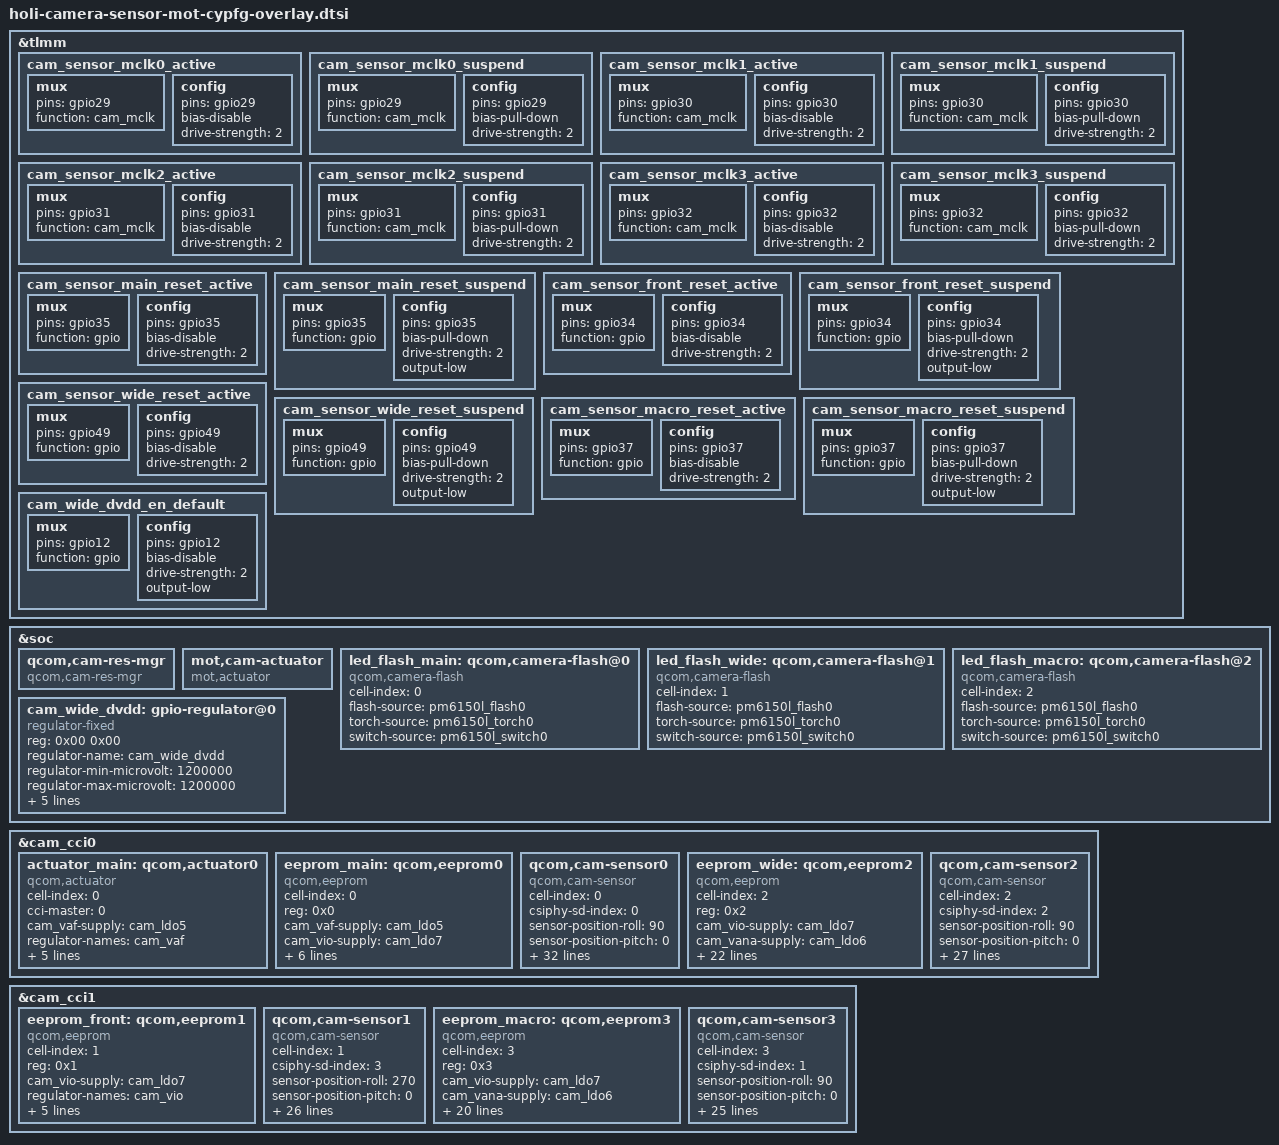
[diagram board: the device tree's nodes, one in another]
#include <dt-bindings/clock/qcom,gcc-holi.h>

&tlmm {
	cam_sensor_mclk0_active: cam_sensor_mclk0_active {
		mux {
			pins = "gpio29";
			function = "cam_mclk";
		};

		config {
			pins = "gpio29";
			bias-disable; /* No PULL */
			drive-strength = <2>; /* 2 MA */
		};
	};

	cam_sensor_mclk0_suspend: cam_sensor_mclk0_suspend {
		mux {
			pins = "gpio29";
			function = "cam_mclk";
		};

		config {
			pins = "gpio29";
			bias-pull-down; /* PULL DOWN */
			drive-strength = <2>; /* 2 MA */
		};
	};

	cam_sensor_mclk1_active: cam_sensor_mclk1_active {
		mux {
			pins = "gpio30";
			function = "cam_mclk";
		};

		config {
			pins = "gpio30";
			bias-disable; /* No PULL */
			drive-strength = <2>;
		};
	};

	cam_sensor_mclk1_suspend: cam_sensor_mclk1_suspend {
		mux {
			pins = "gpio30";
			function = "cam_mclk";
		};

		config {
			pins = "gpio30";
			bias-pull-down; /* PULL DOWN */
			drive-strength = <2>;
		};
	};

	cam_sensor_mclk2_active: cam_sensor_mclk2_active {
		mux {
			pins = "gpio31";
			function = "cam_mclk";
		};

		config {
			pins = "gpio31";
			bias-disable; /* No PULL */
			drive-strength = <2>;
		};
	};

	cam_sensor_mclk2_suspend: cam_sensor_mclk2_suspend {
		mux {
			pins = "gpio31";
			function = "cam_mclk";
		};

		config {
			pins = "gpio31";
			bias-pull-down; /* PULL DOWN */
			drive-strength = <2>;
		};
	};

	cam_sensor_mclk3_active: cam_sensor_mclk3_active {
		mux {
			pins = "gpio32";
			function = "cam_mclk";
		};

		config {
			pins = "gpio32";
			bias-disable; /* No PULL */
			drive-strength = <2>; /* 2 MA */
		};
	};

	cam_sensor_mclk3_suspend: cam_sensor_mclk3_suspend {
		mux {
			pins = "gpio32";
			function = "cam_mclk";
		};

		config {
			pins = "gpio32";
			bias-pull-down; /* PULL DOWN */
			drive-strength = <2>; /* 2 MA */
		};
	};

	cam_sensor_main_reset_active: cam_sensor_main_reset_active {
		mux {
			pins = "gpio35";
			function = "gpio";
		};

		config {
			pins = "gpio35";
			bias-disable; /* No PULL */
			drive-strength = <2>; /* 2 MA */
		};
	};

	cam_sensor_main_reset_suspend: cam_sensor_main_reset_suspend {
		mux {
			pins = "gpio35";
			function = "gpio";
		};

		config {
			pins = "gpio35";
			bias-pull-down; /* PULL DOWN */
			drive-strength = <2>; /* 2 MA */
			output-low;
		};
	};

	cam_sensor_front_reset_active: cam_sensor_front_reset_active {
		mux {
			pins = "gpio34";
			function = "gpio";
		};

		config {
			pins = "gpio34";
			bias-disable; /* No PULL */
			drive-strength = <2>; /* 2 MA */
		};
	};

	cam_sensor_front_reset_suspend: cam_sensor_front_reset_suspend {
		mux {
			pins = "gpio34";
			function = "gpio";
		};

		config {
			pins = "gpio34";
			bias-pull-down; /* PULL DOWN */
			drive-strength = <2>; /* 2 MA */
			output-low;
		};
	};

	cam_sensor_wide_reset_active: cam_sensor_wide_reset_active {
		mux {
			pins = "gpio49";
			function = "gpio";
		};

		config {
			pins = "gpio49";
			bias-disable; /* No PULL */
			drive-strength = <2>; /* 2 MA */
		};
	};

	cam_sensor_wide_reset_suspend: cam_sensor_wide_reset_suspend {
		mux {
			pins = "gpio49";
			function = "gpio";
		};

		config {
			pins = "gpio49";
			bias-pull-down; /* PULL DOWN */
			drive-strength = <2>; /* 2 MA */
			output-low;
		};
	};

	cam_sensor_macro_reset_active: cam_sensor_macro_reset_active {
		mux {
			pins = "gpio37";
			function = "gpio";
		};

		config {
			pins = "gpio37";
			bias-disable; /* No PULL */
			drive-strength = <2>; /* 2 MA */
		};
	};

	cam_sensor_macro_reset_suspend: cam_sensor_macro_reset_suspend {
		mux {
			pins = "gpio37";
			function = "gpio";
		};

		config {
			pins = "gpio37";
			bias-pull-down; /* PULL DOWN */
			drive-strength = <2>; /* 2 MA */
			output-low;
		};
	};

	cam_wide_dvdd_en_default: cam_wide_dvdd_en_default {
		mux {
			pins = "gpio12";
			function = "gpio";
		};

		config {
			pins = "gpio12";
			bias-disable; /* NO PULL */
			drive-strength = <2>; /* 2 MA */
			output-low;
		};
	};
};

&soc {
	qcom,cam-res-mgr {
		compatible = "qcom,cam-res-mgr";
		status = "ok";
	};

	mot,cam-actuator {
		compatible = "mot,actuator";
		status = "ok";
	};

	led_flash_main: qcom,camera-flash@0 {
		cell-index = <0>;
		compatible = "qcom,camera-flash";
		flash-source = <&pm6150l_flash0>;
		torch-source = <&pm6150l_torch0>;
		switch-source = <&pm6150l_switch0>;
		status = "ok";
	};

	led_flash_wide: qcom,camera-flash@1 {
		cell-index = <1>;
		compatible = "qcom,camera-flash";
		flash-source = <&pm6150l_flash0>;
		torch-source = <&pm6150l_torch0>;
		switch-source = <&pm6150l_switch0>;
		status = "ok";
	};

	led_flash_macro: qcom,camera-flash@2 {
		cell-index = <2>;
		compatible = "qcom,camera-flash";
		flash-source = <&pm6150l_flash0>;
		torch-source = <&pm6150l_torch0>;
		switch-source = <&pm6150l_switch0>;
		status = "ok";
	};

	cam_wide_dvdd: gpio-regulator@0{
		compatible = "regulator-fixed";
		reg = <0x00 0x00>;
		regulator-name = "cam_wide_dvdd";
		regulator-min-microvolt = <1200000>;
		regulator-max-microvolt = <1200000>;
		regulator-enable-ramp-delay = <233>;
		enable-active-high;
		gpio = <&tlmm 12 0>;
		pinctrl-names = "default";
		pinctrl-0 = <&cam_wide_dvdd_en_default>;
		vin-supply = <&S2A>;
	};
};

&cam_cci0 {
	actuator_main: qcom,actuator0 {
		cell-index = <0>;
		compatible = "qcom,actuator";
		cci-master = <0>;
		cam_vaf-supply = <&cam_ldo5>;
		regulator-names = "cam_vaf";
		rgltr-cntrl-support;
		rgltr-min-voltage = <2800000>;
		rgltr-max-voltage = <2800000>;
		rgltr-load-current = <100000>;
		status = "ok";
		multi-user-support;
	};

	eeprom_main: qcom,eeprom0 {
		cell-index = <0>;
		reg = <0x0>;
		compatible = "qcom,eeprom";
		cam_vaf-supply = <&cam_ldo5>;
		cam_vio-supply = <&cam_ldo7>;
		regulator-names = "cam_vaf", "cam_vio";
		rgltr-cntrl-support;
		rgltr-min-voltage = <2800000 1800000>;
		rgltr-max-voltage = <2800000 1800000>;
		rgltr-load-current = <100000 120000>;
		cci-master = <0>;
		status = "ok";
	};

	qcom,cam-sensor0 {
		cell-index = <0>;
		compatible = "qcom,cam-sensor";
		csiphy-sd-index = <0>;
		sensor-position-roll = <90>;
		sensor-position-pitch = <0>;
		sensor-position-yaw = <180>;
		actuator-src = <&actuator_main>;
		led-flash-src = <&led_flash_main>;
		eeprom-src = <&eeprom_main>;
		cam_vio-supply = <&cam_ldo7>;
		cam_vana-supply = <&cam_ldo4>;
		cam_vdig-supply = <&cam_ldo2>;
		cam_clk-supply = <&gcc_camss_top_gdsc>;
		cam_vaf-supply = <&cam_ldo5>;
		regulator-names = "cam_vio", "cam_vana", "cam_vdig",
			"cam_clk", "cam_vaf";
		rgltr-cntrl-support;
		rgltr-min-voltage = <1800000 2800000 1050000 0 2800000>;
		rgltr-max-voltage = <1800000 2800000 1050000 0 2800000>;
		rgltr-load-current = <120000 80000 1200000 0 100000>;
		gpio-no-mux = <0>;
		pinctrl-names = "cam_default", "cam_suspend";
		pinctrl-0 = <&cam_sensor_mclk0_active
				&cam_sensor_main_reset_active>;
		pinctrl-1 = <&cam_sensor_mclk0_suspend
				&cam_sensor_main_reset_suspend>;
		gpios = <&tlmm 29 0>,
			<&tlmm 35 0>;
		gpio-reset = <1>;
		gpio-req-tbl-num = <0 1>;
		gpio-req-tbl-flags = <1 0>;
		gpio-req-tbl-label = "CAMIF_MCLK0",
					"CAM_RESET0";
		cci-master = <0>;
		status = "ok";
		clocks = <&gcc GCC_CAMSS_MCLK0_CLK>;
		clock-names = "cam_clk";
		clock-cntl-level = "turbo";
		clock-rates = <24000000>;
	};

	eeprom_wide: qcom,eeprom2 {
		cell-index = <2>;
                reg = <0x2>;
		compatible = "qcom,eeprom";
		cam_vio-supply = <&cam_ldo7>;
		cam_vana-supply = <&cam_ldo6>;
		cam_vdig-supply = <&cam_wide_dvdd>;
		cam_clk-supply = <&gcc_camss_top_gdsc>;
		regulator-names = "cam_vio", "cam_vana", "cam_vdig",
			"cam_clk";
		rgltr-cntrl-support;
		rgltr-min-voltage = <1800000 2800000 1200000 0>;
		rgltr-max-voltage = <1800000 2800000 1200000 0>;
		rgltr-load-current = <120000 80000 1200000 0>;
		gpio-no-mux = <0>;
		pinctrl-names = "cam_default", "cam_suspend";
		pinctrl-0 = <&cam_sensor_mclk1_active
				&cam_sensor_wide_reset_active>;
		pinctrl-1 = <&cam_sensor_mclk1_suspend
				&cam_sensor_wide_reset_suspend>;
		gpios = <&tlmm 30 0>,
			<&tlmm 49 0>;
		gpio-reset = <1>;
		gpio-req-tbl-num = <0 1>;
		gpio-req-tbl-flags = <1 0>;
		gpio-req-tbl-label = "CAMIF_MCLK1",
					"CAM_RESET2";
		cci-master = <1>;
		status = "ok";
		clocks = <&gcc GCC_CAMSS_MCLK1_CLK>;
		clock-names = "cam_clk";
		clock-cntl-level = "turbo";
		clock-rates = <24000000>;
	};

	qcom,cam-sensor2 {
		cell-index = <2>;
		compatible = "qcom,cam-sensor";
		csiphy-sd-index = <2>;
		sensor-position-roll = <90>;
		sensor-position-pitch = <0>;
		sensor-position-yaw = <180>;
		led-flash-src = <&led_flash_wide>;
		eeprom-src = <&eeprom_wide>;
		cam_vio-supply = <&cam_ldo7>;
		cam_vana-supply = <&cam_ldo6>;
		cam_vdig-supply = <&cam_wide_dvdd>;
		cam_clk-supply = <&gcc_camss_top_gdsc>;
		regulator-names = "cam_vio", "cam_vana", "cam_vdig",
			"cam_clk";
		rgltr-cntrl-support;
		rgltr-min-voltage = <1800000 2800000 1200000 0>;
		rgltr-max-voltage = <1800000 2800000 1200000 0>;
		rgltr-load-current = <120000 80000 1200000 0>;
		gpio-no-mux = <0>;
		pinctrl-names = "cam_default", "cam_suspend";
		pinctrl-0 = <&cam_sensor_mclk1_active
				&cam_sensor_wide_reset_active>;
		pinctrl-1 = <&cam_sensor_mclk1_suspend
				&cam_sensor_wide_reset_suspend>;
		gpios = <&tlmm 30 0>,
			<&tlmm 49 0>;
		gpio-reset = <1>;
		gpio-req-tbl-num = <0 1>;
		gpio-req-tbl-flags = <1 0>;
		gpio-req-tbl-label = "CAMIF_MCLK1",
					"CAM_RESET2";
		cci-master = <1>;
		status = "ok";
		clocks = <&gcc GCC_CAMSS_MCLK1_CLK>;
		clock-names = "cam_clk";
		clock-cntl-level = "turbo";
		clock-rates = <24000000>;
	};
};

&cam_cci1 {
	eeprom_front: qcom,eeprom1 {
		cell-index = <1>;
		reg = <0x1>;
		compatible = "qcom,eeprom";
		cam_vio-supply = <&cam_ldo7>;
		regulator-names = "cam_vio";
		rgltr-cntrl-support;
		rgltr-min-voltage = <1800000>;
		rgltr-max-voltage = <1800000>;
		rgltr-load-current = <120000>;
		cci-master = <0>;
		status = "ok";
	};

	qcom,cam-sensor1 {
		cell-index = <1>;
		compatible = "qcom,cam-sensor";
		csiphy-sd-index = <3>;
		sensor-position-roll = <270>;
		sensor-position-pitch = <0>;
		sensor-position-yaw = <0>;
		eeprom-src = <&eeprom_front>;
		cam_vio-supply = <&cam_ldo7>;
		cam_vana-supply = <&cam_ldo3>;
		cam_vdig-supply = <&cam_ldo1>;
		cam_clk-supply = <&gcc_camss_top_gdsc>;
		regulator-names = "cam_vio", "cam_vana", "cam_vdig",
			"cam_clk";
		rgltr-cntrl-support;
		rgltr-min-voltage = <1800000 2800000 1050000 0>;
		rgltr-max-voltage = <1800000 2800000 1050000 0>;
		rgltr-load-current = <120000 80000 1200000 0>;
		gpio-no-mux = <0>;
		pinctrl-names = "cam_default", "cam_suspend";
		pinctrl-0 = <&cam_sensor_mclk3_active
				&cam_sensor_front_reset_active>;
		pinctrl-1 = <&cam_sensor_mclk3_suspend
				&cam_sensor_front_reset_suspend>;
		gpios = <&tlmm 32 0>,
			<&tlmm 34 0>;
		gpio-reset = <1>;
		gpio-req-tbl-num = <0 1>;
		gpio-req-tbl-flags = <1 0>;
		gpio-req-tbl-label = "CAMIF_MCLK3",
					"CAM_RESET1";
		cci-master = <0>;
		status = "ok";
		clocks = <&gcc GCC_CAMSS_MCLK3_CLK>;
		clock-names = "cam_clk";
		clock-cntl-level = "turbo";
		clock-rates = <24000000>;
	};

	eeprom_macro: qcom,eeprom3 {
		cell-index = <3>;
                reg = <0x3>;
		compatible = "qcom,eeprom";
		cam_vio-supply = <&cam_ldo7>;
		cam_vana-supply = <&cam_ldo6>;
		cam_clk-supply = <&gcc_camss_top_gdsc>;
		regulator-names = "cam_vio","cam_vana", "cam_clk";
		rgltr-cntrl-support;
		rgltr-min-voltage = <1800000 2800000 0>;
		rgltr-max-voltage = <1800000 2800000 0>;
		rgltr-load-current = <120000 120000  0>;
		gpio-no-mux = <0>;
		pinctrl-names = "cam_default", "cam_suspend";
		pinctrl-0 = <&cam_sensor_mclk2_active
				&cam_sensor_macro_reset_active>;
		pinctrl-1 = <&cam_sensor_mclk2_suspend
				&cam_sensor_macro_reset_suspend>;
		gpios = <&tlmm 31 0>,
			<&tlmm 37 0>;
		gpio-reset = <1>;
		gpio-req-tbl-num = <0 1>;
		gpio-req-tbl-flags = <1 0>;
		gpio-req-tbl-label = "CAMIF_MCLK2",
					"CAM_RESET3";
		cci-master = <0>;
		status = "ok";
		clocks = <&gcc GCC_CAMSS_MCLK2_CLK>;
		clock-names = "cam_clk";
		clock-cntl-level = "turbo";
		clock-rates = <24000000>;
	};

	qcom,cam-sensor3 {
		cell-index = <3>;
		compatible = "qcom,cam-sensor";
		csiphy-sd-index = <1>;
		sensor-position-roll = <90>;
		sensor-position-pitch = <0>;
		sensor-position-yaw = <180>;
		led-flash-src = <&led_flash_macro>;
		eeprom-src = <&eeprom_macro>;
		cam_vio-supply = <&cam_ldo7>;
		cam_vana-supply = <&cam_ldo6>;
		cam_clk-supply = <&gcc_camss_top_gdsc>;
		regulator-names = "cam_vio","cam_vana", "cam_clk";
		rgltr-cntrl-support;
		rgltr-min-voltage = <1800000 2800000 0>;
		rgltr-max-voltage = <1800000 2800000 0>;
		rgltr-load-current = <120000 120000  0>;
		gpio-no-mux = <0>;
		pinctrl-names = "cam_default", "cam_suspend";
		pinctrl-0 = <&cam_sensor_mclk2_active
				&cam_sensor_macro_reset_active>;
		pinctrl-1 = <&cam_sensor_mclk2_suspend
				&cam_sensor_macro_reset_suspend>;
		gpios = <&tlmm 31 0>,
			<&tlmm 37 0>;
		gpio-reset = <1>;
		gpio-req-tbl-num = <0 1>;
		gpio-req-tbl-flags = <1 0>;
		gpio-req-tbl-label = "CAMIF_MCLK2",
					"CAM_RESET3";
		cci-master = <0>;
		status = "ok";
		clocks = <&gcc GCC_CAMSS_MCLK2_CLK>;
		clock-names = "cam_clk";
		clock-cntl-level = "turbo";
		clock-rates = <24000000>;
	};
};
